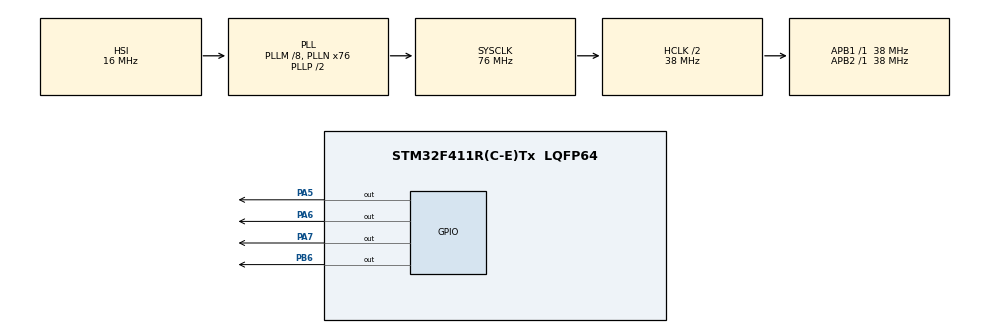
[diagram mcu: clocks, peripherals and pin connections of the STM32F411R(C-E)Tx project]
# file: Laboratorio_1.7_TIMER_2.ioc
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Mcu.Family=STM32F4
Mcu.Name=STM32F411R(C-E)Tx
Mcu.Package=LQFP64
NVIC.PriorityGroup=NVIC_PRIORITYGROUP_0
NVIC.TIM1_BRK_TIM9_IRQn=true\:0\:0\:false\:false\:true\:true\:true\:true
NVIC.TIM1_CC_IRQn=true\:0\:0\:false\:false\:true\:true\:true\:true
NVIC.TIM1_TRG_COM_TIM11_IRQn=true\:0\:0\:false\:false\:true\:true\:true\:true
NVIC.TIM1_UP_TIM10_IRQn=true\:0\:0\:false\:false\:true\:true\:true\:true
NVIC.TIM2_IRQn=true\:0\:0\:false\:false\:true\:true\:true\:true
PA13.GPIO_Label=TMS
PA13.Mode=Serial_Wire
PA13.Signal=SYS_JTMS-SWDIO
PA14.GPIO_Label=TCK
PA14.Mode=Serial_Wire
PA14.Signal=SYS_JTCK-SWCLK
PA5.Signal=GPIO_Output
PA6.Signal=GPIO_Output
PA7.Signal=GPIO_Output
PB6.Signal=GPIO_Output
PH0\ -\ OSC_IN.Mode=HSE-External-Oscillator
PH0\ -\ OSC_IN.Signal=RCC_OSC_IN
PH1\ -\ OSC_OUT.Mode=HSE-External-Oscillator
PH1\ -\ OSC_OUT.Signal=RCC_OSC_OUT
ProjectManager.HeapSize=0x200
ProjectManager.StackSize=0x400
ProjectManager.TargetToolchain=STM32CubeIDE
RCC.48MHZClocksFreq_Value=38000000
RCC.AHBCLKDivider=RCC_SYSCLK_DIV2
RCC.AHBFreq_Value=38000000
RCC.APB1Freq_Value=38000000
RCC.APB1TimFreq_Value=38000000
RCC.APB2Freq_Value=38000000
RCC.APB2TimFreq_Value=38000000
RCC.CortexFreq_Value=38000000
RCC.FLatency-AdvancedSettings=FLASH_LATENCY_1
RCC.HCLKFreq_Value=38000000
RCC.HSE_VALUE=8000000
RCC.HSI_VALUE=16000000
RCC.LSE_VALUE=32768
RCC.PLLM=8
RCC.PLLN=76
RCC.SYSCLKFreq_VALUE=76000000
RCC.SYSCLKSource=RCC_SYSCLKSOURCE_PLLCLK
RCC.VCOOutputFreq_Value=152000000
TIM1.Period=9
TIM1.Prescaler=1899
TIM2.Period=9
TIM2.Prescaler=1899
VP_TIM1_VS_ClockSourceINT.Mode=Internal
VP_TIM2_VS_ClockSourceINT.Mode=Internal
board=NUCLEO-F411RE

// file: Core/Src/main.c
/* USER CODE BEGIN Header */
/**
  ******************************************************************************
  * @file           : main.c
  * @brief          : Main program body
  ******************************************************************************
  * @attention
  *
  * Copyright (c) 2023 STMicroelectronics.
  * All rights reserved.
  *
  * This software is licensed under terms that can be found in the LICENSE file
  * in the root directory of this software component.
  * If no LICENSE file comes with this software, it is provided AS-IS.
  *
  ******************************************************************************
  */
/* USER CODE END Header */
#include "main.h"

TIM_HandleTypeDef htim1;
TIM_HandleTypeDef htim2;

void SystemClock_Config(void);
static void MX_GPIO_Init(void);
static void MX_TIM1_Init(void);
static void MX_TIM2_Init(void);
/* USER CODE BEGIN PFP */
void HAL_TIM_PeriodElapsedCallback(TIM_HandleTypeDef *htim)
{
	if(htim->Instance ==TIM1)
		HAL_GPIO_TogglePin(GPIOA, GPIO_PIN_6);
	if(htim->Instance ==TIM2)
		HAL_GPIO_TogglePin(GPIOA, GPIO_PIN_5);

}
/* USER CODE END PFP */

int main(void)
{

  /* MCU Configuration--------------------------------------------------------*/

  /* Reset of all peripherals, Initializes the Flash interface and the Systick. */
  HAL_Init();

  /* Configure the system clock */
  SystemClock_Config();

  /* Initialize all configured peripherals */
  MX_GPIO_Init();
  MX_TIM1_Init();
  MX_TIM2_Init();
  /* USER CODE BEGIN 2 */
  HAL_TIM_Base_Start_IT(&htim1); //activación INT del TMR1
  HAL_TIM_Base_Start_IT(&htim2); //activación INT del TMR2
  /* USER CODE END 2 */

  /* Infinite loop */
  while (1)
  {

  }
}

void SystemClock_Config(void)
{
  RCC_OscInitTypeDef RCC_OscInitStruct = {0};
  RCC_ClkInitTypeDef RCC_ClkInitStruct = {0};

  /** Configure the main internal regulator output voltage
  */
  __HAL_RCC_PWR_CLK_ENABLE();
  __HAL_PWR_VOLTAGESCALING_CONFIG(PWR_REGULATOR_VOLTAGE_SCALE1);

  /** Initializes the RCC Oscillators according to the specified parameters
  * in the RCC_OscInitTypeDef structure.
  */
  RCC_OscInitStruct.OscillatorType = RCC_OSCILLATORTYPE_HSI;
  RCC_OscInitStruct.HSIState = RCC_HSI_ON;
  RCC_OscInitStruct.HSICalibrationValue = RCC_HSICALIBRATION_DEFAULT;
  RCC_OscInitStruct.PLL.PLLState = RCC_PLL_ON;
  RCC_OscInitStruct.PLL.PLLSource = RCC_PLLSOURCE_HSI;
  RCC_OscInitStruct.PLL.PLLM = 8;
  RCC_OscInitStruct.PLL.PLLN = 76;
  RCC_OscInitStruct.PLL.PLLP = RCC_PLLP_DIV2;
  RCC_OscInitStruct.PLL.PLLQ = 4;
  if (HAL_RCC_OscConfig(&RCC_OscInitStruct) != HAL_OK)
  {
    Error_Handler();
  }

  /** Initializes the CPU, AHB and APB buses clocks
  */
  RCC_ClkInitStruct.ClockType = RCC_CLOCKTYPE_HCLK|RCC_CLOCKTYPE_SYSCLK
                              |RCC_CLOCKTYPE_PCLK1|RCC_CLOCKTYPE_PCLK2;
  RCC_ClkInitStruct.SYSCLKSource = RCC_SYSCLKSOURCE_PLLCLK;
  RCC_ClkInitStruct.AHBCLKDivider = RCC_SYSCLK_DIV2;
  RCC_ClkInitStruct.APB1CLKDivider = RCC_HCLK_DIV1;
  RCC_ClkInitStruct.APB2CLKDivider = RCC_HCLK_DIV1;

  if (HAL_RCC_ClockConfig(&RCC_ClkInitStruct, FLASH_LATENCY_1) != HAL_OK)
  {
    Error_Handler();
  }
}

static void MX_TIM1_Init(void)
{

  TIM_ClockConfigTypeDef sClockSourceConfig = {0};
  TIM_MasterConfigTypeDef sMasterConfig = {0};

  htim1.Instance = TIM1;
  htim1.Init.Prescaler = 1899;
  htim1.Init.CounterMode = TIM_COUNTERMODE_UP;
  htim1.Init.Period = 9;
  htim1.Init.ClockDivision = TIM_CLOCKDIVISION_DIV1;
  htim1.Init.RepetitionCounter = 0;
  htim1.Init.AutoReloadPreload = TIM_AUTORELOAD_PRELOAD_DISABLE;
  if (HAL_TIM_Base_Init(&htim1) != HAL_OK)
  {
    Error_Handler();
  }
  sClockSourceConfig.ClockSource = TIM_CLOCKSOURCE_INTERNAL;
  if (HAL_TIM_ConfigClockSource(&htim1, &sClockSourceConfig) != HAL_OK)
  {
    Error_Handler();
  }
  sMasterConfig.MasterOutputTrigger = TIM_TRGO_RESET;
  sMasterConfig.MasterSlaveMode = TIM_MASTERSLAVEMODE_DISABLE;
  if (HAL_TIMEx_MasterConfigSynchronization(&htim1, &sMasterConfig) != HAL_OK)
  {
    Error_Handler();
  }

}

static void MX_TIM2_Init(void)
{

  TIM_ClockConfigTypeDef sClockSourceConfig = {0};
  TIM_MasterConfigTypeDef sMasterConfig = {0};

  htim2.Instance = TIM2;
  htim2.Init.Prescaler = 1899;
  htim2.Init.CounterMode = TIM_COUNTERMODE_UP;
  htim2.Init.Period = 9;
  htim2.Init.ClockDivision = TIM_CLOCKDIVISION_DIV1;
  htim2.Init.AutoReloadPreload = TIM_AUTORELOAD_PRELOAD_DISABLE;
  if (HAL_TIM_Base_Init(&htim2) != HAL_OK)
  {
    Error_Handler();
  }
  sClockSourceConfig.ClockSource = TIM_CLOCKSOURCE_INTERNAL;
  if (HAL_TIM_ConfigClockSource(&htim2, &sClockSourceConfig) != HAL_OK)
  {
    Error_Handler();
  }
  sMasterConfig.MasterOutputTrigger = TIM_TRGO_RESET;
  sMasterConfig.MasterSlaveMode = TIM_MASTERSLAVEMODE_DISABLE;
  if (HAL_TIMEx_MasterConfigSynchronization(&htim2, &sMasterConfig) != HAL_OK)
  {
    Error_Handler();
  }

}

static void MX_GPIO_Init(void)
{
  GPIO_InitTypeDef GPIO_InitStruct = {0};

  /* GPIO Ports Clock Enable */
  __HAL_RCC_GPIOH_CLK_ENABLE();
  __HAL_RCC_GPIOA_CLK_ENABLE();
  __HAL_RCC_GPIOB_CLK_ENABLE();

  /*Configure GPIO pin Output Level */
  HAL_GPIO_WritePin(GPIOA, GPIO_PIN_5|GPIO_PIN_6|GPIO_PIN_7, GPIO_PIN_RESET);

  /*Configure GPIO pin Output Level */
  HAL_GPIO_WritePin(GPIOB, GPIO_PIN_6, GPIO_PIN_RESET);

  /*Configure GPIO pins : PA5 PA6 PA7 */
  GPIO_InitStruct.Pin = GPIO_PIN_5|GPIO_PIN_6|GPIO_PIN_7;
  GPIO_InitStruct.Mode = GPIO_MODE_OUTPUT_PP;
  GPIO_InitStruct.Pull = GPIO_NOPULL;
  GPIO_InitStruct.Speed = GPIO_SPEED_FREQ_LOW;
  HAL_GPIO_Init(GPIOA, &GPIO_InitStruct);

  /*Configure GPIO pin : PB6 */
  GPIO_InitStruct.Pin = GPIO_PIN_6;
  GPIO_InitStruct.Mode = GPIO_MODE_OUTPUT_PP;
  GPIO_InitStruct.Pull = GPIO_NOPULL;
  GPIO_InitStruct.Speed = GPIO_SPEED_FREQ_LOW;
  HAL_GPIO_Init(GPIOB, &GPIO_InitStruct);

}

void Error_Handler(void)
{
  __disable_irq();
  while (1)
  {
  }
}
